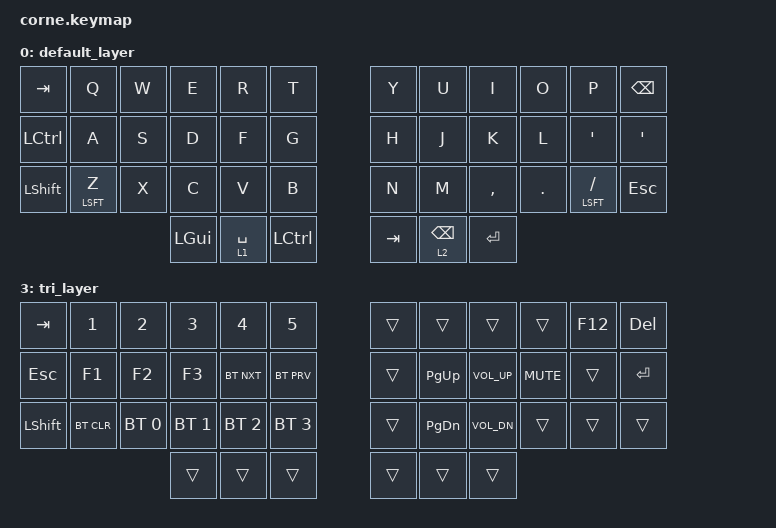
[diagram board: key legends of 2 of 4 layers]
/*
 * Copyright (c) 2020 The ZMK Contributors
 *
 * SPDX-License-Identifier: MIT
 */

#include <behaviors.dtsi>
#include <dt-bindings/zmk/keys.h>
#include <dt-bindings/zmk/bt.h>

/ { 

    combos {
        compatible = "zmk,combos";
        combo_esc {
            timeout-ms = <50>;
            key-positions = <13 14>;
            bindings = <&kp ESC>;
        };
        
         combo_tab {
            timeout-ms = <50>;
            key-positions = <1 2>;
            bindings = <&kp TAB>;
        };
        
            combo_bspc {
            timeout-ms = <50>;
            key-positions = <9 10>;
            bindings = <&kp BSPC>;
        };
        
                    combo_lalt {
            timeout-ms = <50>;
            key-positions = <14 15>;
            bindings = <&kp LALT>;
        };
        
                           combo_lgui {
            timeout-ms = <50>;
            key-positions = <15 16>;
            bindings = <&kp LGUI>;
        };
        
           combo_ret {
            timeout-ms = <50>;
            key-positions = <21 22>;
            bindings = <&kp RET>;
        };
        
    				combo_ralt {                                                                                                                          
            timeout-ms = <50>;                                                                                                                    
            key-positions = <20 19>;                                                                                                                
            bindings = <&kp RALT>;                                                                                                                
         };

						combo_rgui {
						timeout-ms = <50>;
						key-positions = <20 21>;
						bindings = <&kp RGUI>;
	 };
};
    
    
        keymap {
                compatible = "zmk,keymap";

                default_layer {
// -----------------------------------------------------------------------------------------
// |  TAB |  Q  |  W  |  E  |  R  |  T  |   |  Y  |  U   |  I  |  O  |  P  | BKSP |
// | CTRL |  A  |  S  |  D  |  F  |  G  |   |  H  |  J   |  K  |  L  |  ;  |  '   |
// | SHFT |  Z  |  X  |  C  |  V  |  B  |   |  N  |  M   |  ,  |  .  |  /  | ESC  |
//                    | GUI | LWR | SPC |   | ENT | RSE  | ALT |
                        bindings = <
   &kp TAB   &kp Q &kp W &kp E &kp R &kp T   &kp Y &kp U  &kp I     &kp O   &kp P    &kp BSPC
   &kp LCTRL &kp A &kp S &kp D &kp F &kp G   &kp H &kp J  &kp K     &kp L   &kp SQT &kp SQT
   &kp LSHFT &mt LSFT Z &kp X &kp C &kp V &kp B   &kp N &kp M  &kp COMMA &kp DOT &mt LSFT FSLH &kp ESC
               &kp LGUI &lt 1 SPC &kp LCTL   &kp TAB &lt 2 BSPC &kp RET
                        >;
                };
                lower_layer {
// -----------------------------------------------------------------------------------------
// |  TAB |  1  |  2  |  3  |  4  |  5  |   |  6  |  7  |  8  |  9  |  0  | BKSP |
// | BTCLR| BT1 | BT2 | BT3 | BT4 | BT5 |   | LFT | DWN |  UP | RGT |     |      |
// | SHFT |     |     |     |     |     |   |     |     |     |     |     |      |
//                    | GUI |     | SPC |   | ENT |     | ALT |
                        bindings = <
   &kp TAB &kp TAB &kp GRAVE &kp F2  &kp F3 &kp F4 &kp F5		    &kp ASTRK &kp NUM_7  &kp NUM_8 &kp NUM_9 &kp BSPC &kp BSPC &kp RET
   &kp ESC &kp F6    &kp F7      &kp F8    &kp F9    &kp F10 		  &kp MINUS &kp NUM_4  &kp NUM_5 &kp NUM_6 &kp PLUS &kp RET
   &kp ESC &kp F1    &kp TILDE 	&kp TILDE &kp F11   &kp F12 	    &kp NUM_0 &kp NUM_1  &kp NUM_2 &kp NUM_3  &kp DEL &kp RET
                          	        &kp LGUI     &mo 1  &kp LGUI  					&kp RGUI &mo 2   &kp RALT
                        >;
                };

                raise_layer {
// -----------------------------------------------------------------------------------------
// |  TAB |  !  |  @  |  #  |  $  |  %  |   |  ^  |  &  |  *  |  (  |  )  | BKSP |
// | CTRL |     |     |     |     |     |   |  -  |  =  |  [  |  ]  |  \  |  `   |
// | SHFT |     |     |     |     |     |   |  _  |  +  |  {  |  }  | "|" |  ~   |
//                    | GUI |     | SPC |   | ENT |     | ALT |
                        bindings = <
   &kp  TAB  &kp EXCL  &kp AT &kp HASH  &kp DLLR  &kp PRCNT    			&kp CARET  &kp AMPS &kp ASTRK &kp LPAR &kp RPAR &kp BSPC
   &kp LCTRL &kp LBKT  &kp RBKT  &kp LBRC &kp RBRC &kp PIPE         &kp LEFT &kp DOWN  &kp UP  &kp RIGHT   &kp SEMI &kp GRAVE
   &kp LSHFT &kp LSFT  &kp KPLS &kp LBKT &kp RBKT   &kp BSLH    			&kp QMARK &kp EQUAL &kp PIPE &kp MINUS  &kp UNDER &kp TILDE
                    	     &kp LGUI &mo 3 &kp LCTL  				&kp SPC  &mo 2&mo 3 &kp LCTL  				&kp SPC  &mo 2  &kp RALT
                        >;
               		};

tri_layer {
		bindings = <
&kp TAB &kp NUM_1  &kp NUM_2    &kp NUM_3    &kp NUM_4    &kp NUM_5 			&trans &trans   &trans   &trans  &kp F12 &kp DEL
&kp ESC &kp F1 &kp F2 &kp F3 &bt BT_NXT &bt BT_PRV					&trans &kp PG_UP  &kp K_VOL_UP &kp K_MUTE &trans &kp RET
&kp LSHFT &bt BT_CLR  &bt BT_SEL 0 &bt BT_SEL 1 &bt BT_SEL 2 &bt BT_SEL 3	   				&trans &kp PG_DN  &kp K_VOL_DN  &trans &trans &trans
					 &trans &trans &trans  					&trans &trans &trans
		>;
		};
};
};
